# ATmega128RFA1 device description
Architecture: AVR8; Family: megaAVR
Registers are 8-bit, access not given, no defined reset value unless marked. A register's access mark holds for its fields unless they carry their own. Offsets are from the block's base; [hi:lo] are bit positions; {n}, {i} and the like mark numbered series; 'fields as' and 'values as' point back to an identical list.

## BOOT_LOAD — Bootloader
Instances: BOOT_LOAD 0x00
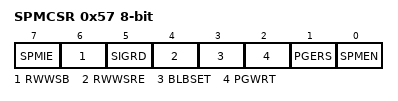
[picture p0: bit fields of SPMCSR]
0x57 SPMCSR — Store Program Memory Control Register
  [7] SPMIE — SPM Interrupt Enable
  [6] RWWSB — Read While Write Section Busy
  [5] SIGRD — Signature Row Read
  [4] RWWSRE — Read While Write Section Read Enable
  [3] BLBSET — Boot Lock Bit Set
  [2] PGWRT — Page Write
  [1] PGERS — Page Erase
  [0] SPMEN — Store Program Memory Enable

## CPU — CPU Registers
Instances: CPU 0x00
Parameters: CORE_VERSION=V3
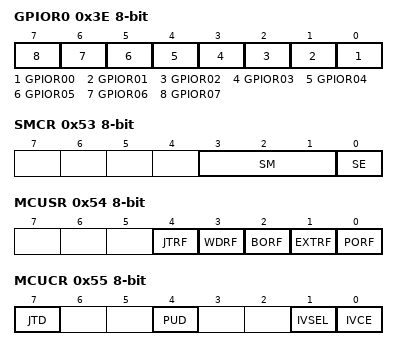
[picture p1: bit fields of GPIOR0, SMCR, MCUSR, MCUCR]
0x3E GPIOR0 — General Purpose IO Register 0
  [n] GPIOR{n:02} (n=0..7) — General Purpose I/O Register 0 Value
0x4A GPIOR1 — General Purpose IO Register 1
  [7:0] GPIOR (bit 10 of the value upward) — General Purpose I/O Register 1 Value
0x4B GPIOR2 — General Purpose I/O Register 2
  [7:0] GPIOR (bit 20 of the value upward) — General Purpose I/O Register 2 Value
0x53 SMCR — Sleep Mode Control Register
  [3:1] SM — Sleep Mode Select bits
    0=IDLE; 1=ADC (ADC Noise Reduction (If Available)); 2=PDOWN (Power Down); 3=PSAVE (Power Save); 6=STDBY (Standby); 7=ESTDBY (Extended Standby)
  [0] SE — Sleep Enable
0x54 MCUSR — MCU Status Register
  [4] JTRF — JTAG Reset Flag
  [3] WDRF — Watchdog Reset Flag
  [2] BORF — Brown-out Reset Flag
  [1] EXTRF — External Reset Flag
  [0] PORF — Power-on Reset Flag
0x55 MCUCR — MCU Control Register
  [7] JTD — JTAG Interface Disable
  [4] PUD — Pull-up Disable
  [1] IVSEL — Interrupt Vector Select
  [0] IVCE — Interrupt Vector Change Enable
0x5B RAMPZ — Extended Z-pointer Register for ELPM/SPM
  [1:0] RAMPZ — Extended Z-Pointer Value
    0=Default value of Z-pointer MSB's
0x5D SP 16-bit — Stack Pointer
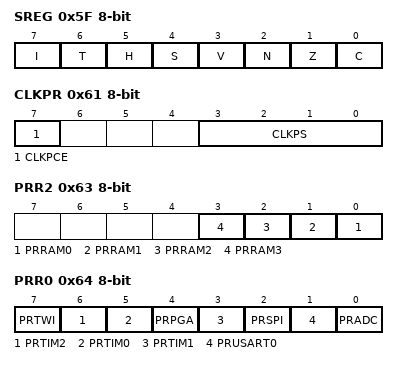
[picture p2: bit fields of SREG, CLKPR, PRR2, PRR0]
0x5F SREG — Status Register
  [7] I — Global Interrupt Enable
  [6] T — Bit Copy Storage
  [5] H — Half Carry Flag
  [4] S — Sign Bit
  [3] V — Two's Complement Overflow Flag
  [2] N — Negative Flag
  [1] Z — Zero Flag
  [0] C — Carry Flag
0x61 CLKPR — Clock Prescale Register
  [7] CLKPCE — Clock Prescaler Change Enable
  [3:0] CLKPS — Clock Prescaler Select Bits
    0=Division factor 1 / RC-Oscillator 2; 1=Division factor 2 / RC-Oscillator 4; 2=Division factor 4 / RC-Oscillator 8; 3=Division factor 8 / RC-Oscillator 16; 4=Division factor 16 / RC-Oscillator 32; 5=Division factor 32 / RC-Oscillator 64; 6=Division factor 64 / RC-Oscillator 128; 7=Division factor 128 / RC-Oscillator 256; 8=Division factor 256 / RC-Oscillator 512; 15=Division factor 1 only permitted for RC-Oscillator. Flash and EEPROM programming is not allowed.
0x63 PRR2 — Power Reduction Register 2
  [n] PRRAM{n} (n=0..3) — Power Reduction SRAM{n}
0x64 PRR0 — Power Reduction Register0
  [7] PRTWI — Power Reduction TWI
  [6] PRTIM2 — Power Reduction Timer/Counter2
  [5] PRTIM0 — Power Reduction Timer/Counter0
  [4] PRPGA — Power Reduction PGA
  [3] PRTIM1 — Power Reduction Timer/Counter1
  [2] PRSPI — Power Reduction Serial Peripheral Interface
  [1] PRUSART0 — Power Reduction USART0
  [0] PRADC — Power Reduction ADC
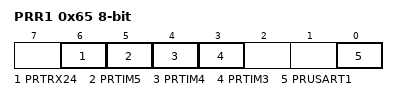
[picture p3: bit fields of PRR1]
0x65 PRR1 — Power Reduction Register 1
  [6] PRTRX24 — Power Reduction Transceiver
  [5] PRTIM5 — Power Reduction Timer/Counter5
  [4] PRTIM4 — Power Reduction Timer/Counter4
  [3] PRTIM3 — Power Reduction Timer/Counter3
  [0] PRUSART1 — Power Reduction USART1
0x66 OSCCAL — Oscillator Calibration Value
  [7:0] CAL — Oscillator Calibration Tuning Value
    0=Calibration value for lowest oscillator frequency; 127=End value of low frequency range calibration; 128=Start value of high frequency range calibration; 255=Calibration value for highest oscillator frequency
  [7:0] OSCCAL — Oscillator Calibration
Value list OSCCAL_VALUE_ADDRESSES: 0=8_0_MHz

## FLASH — FLASH Controller
Instances: FLASH 0x00
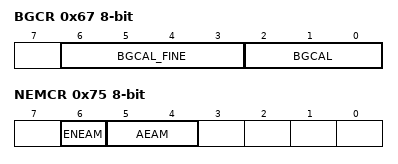
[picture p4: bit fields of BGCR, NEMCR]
0x67 BGCR — Reference Voltage Calibration Register
  [6:3] BGCAL_FINE — Fine Calibration Bits
    0=Center value; 1=Voltage step up; 8=Voltage step down; 7=Setting for highest voltage; 15=Setting for lowest voltage
  [2:0] BGCAL — Coarse Calibration Bits
    4=Center value; 3=Voltage step up; 5=Voltage step down; 0=Setting for highest voltage; 7=Setting for lowest voltage
0x75 NEMCR — Flash Extended-Mode Control-Register
  [6] ENEAM — Enable Extended Address Mode for Extra Rows
  [5:4] AEAM — Address for Extended Address Mode of Extra Rows
    0=Factory Row; 1=User Row 1; 2=User Row 2; 3=User Row 3

## PWRCTRL — Power Controller
Instances: PWRCTRL 0x00
0x55 MCUCR — MCU Control Register
  [4] PUD — Pull-up Disable
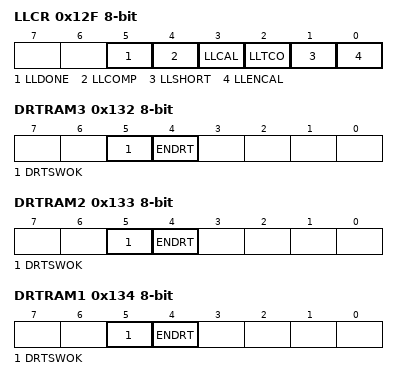
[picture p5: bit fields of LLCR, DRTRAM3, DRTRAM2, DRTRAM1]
0x12F LLCR — Low Leakage Voltage Regulator Control Register
  [5] LLDONE — Calibration Done
  [4] LLCOMP — Comparator Output
  [3] LLCAL — Calibration Active
  [2] LLTCO — Temperature Coefficient of Current Source
  [1] LLSHORT — Short Lower Calibration Circuit
  [0] LLENCAL — Enable Automatic Calibration
0x130 LLDRL — Low Leakage Voltage Regulator Data Register (Low-Byte)
  [3:0] LLDRL — Low-Byte Data Register Bits
    0=Calibration limit for fast process corner/high output voltage; 8=Calibration limit for slow process corner/low output voltage
0x131 LLDRH — Low Leakage Voltage Regulator Data Register (High-Byte)
  [4:0] LLDRH — High-Byte Data Register Bits
    0=Calibration limit for fast process corner/high output voltage; 16=Calibration limit for slow process corner/low output voltage
0x132 DRTRAM3 — Data Retention Configuration Register of SRAM 3
  [5] DRTSWOK — DRT Switch OK
  [4] ENDRT — Enable SRAM Data Retention
0x133 DRTRAM2 — Data Retention Configuration Register of SRAM 2
  [5] DRTSWOK — DRT Switch OK
  [4] ENDRT — Enable SRAM Data Retention
0x134 DRTRAM1 — Data Retention Configuration Register of SRAM 1
  [5] DRTSWOK — DRT Switch OK
  [4] ENDRT — Enable SRAM Data Retention
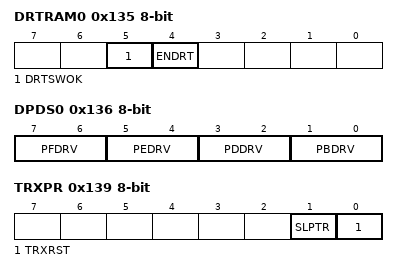
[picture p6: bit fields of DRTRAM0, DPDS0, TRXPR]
0x135 DRTRAM0 — Data Retention Configuration Register of SRAM 0
  [5] DRTSWOK — DRT Switch OK
  [4] ENDRT — Enable SRAM Data Retention
0x136 DPDS0 — Port Driver Strength Register 0
  [all] fields
    0=PAD_IO_2MA (2 mA); 1=PAD_IO_4MA (4 mA); 2=PAD_IO_6MA (6 mA); 3=PAD_IO_8MA (8 mA)
  [7:6] PFDRV — Driver Strength Port F
  [5:4] PEDRV — Driver Strength Port E
  [3:2] PDDRV — Driver Strength Port D
  [1:0] PBDRV — Driver Strength Port B
0x137 DPDS1 — Port Driver Strength Register 1
  [1:0] PGDRV — Driver Strength Port G
    values as the fields of DPDS0
0x139 TRXPR — Transceiver Pin Register
  [1] SLPTR — Multi-purpose Transceiver Control Bit
  [0] TRXRST — Force Transceiver Reset
